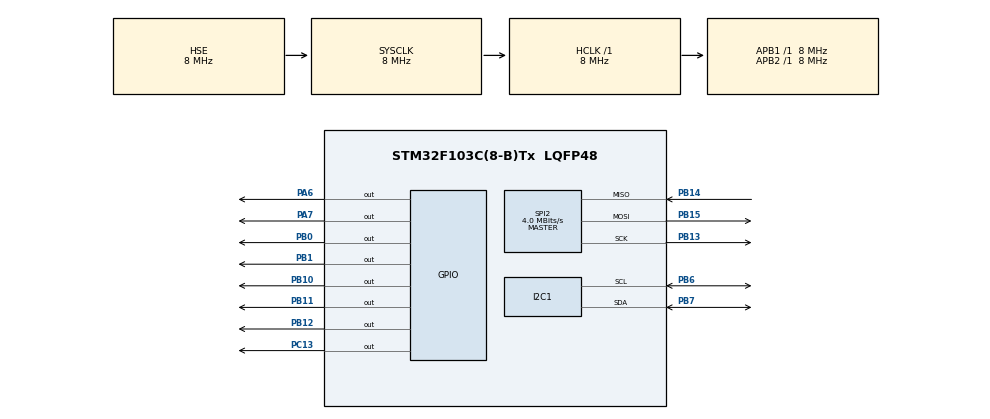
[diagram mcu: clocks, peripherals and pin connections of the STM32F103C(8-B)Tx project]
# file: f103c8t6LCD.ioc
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ADC1.Channel-0\#ChannelRegularConversion=ADC_CHANNEL_TEMPSENSOR
ADC1.NbrOfConversionFlag=1
ADC1.Rank-0\#ChannelRegularConversion=1
ADC1.SamplingTime-0\#ChannelRegularConversion=ADC_SAMPLETIME_1CYCLE_5
ADC1.master=1
Mcu.Family=STM32F1
Mcu.Name=STM32F103C(8-B)Tx
Mcu.Package=LQFP48
NVIC.PriorityGroup=NVIC_PRIORITYGROUP_4
PA6.Signal=GPIO_Output
PA7.Signal=GPIO_Output
PB0.Signal=GPIO_Output
PB1.Signal=GPIO_Output
PB10.Signal=GPIO_Output
PB11.Signal=GPIO_Output
PB12.Signal=GPIO_Output
PB13.Mode=Full_Duplex_Master
PB13.Signal=SPI2_SCK
PB14.Mode=Full_Duplex_Master
PB14.Signal=SPI2_MISO
PB15.Mode=Full_Duplex_Master
PB15.Signal=SPI2_MOSI
PB6.Mode=I2C
PB6.Signal=I2C1_SCL
PB7.Mode=I2C
PB7.Signal=I2C1_SDA
PC13-TAMPER-RTC.Signal=GPIO_Output
PC14-OSC32_IN.Mode=LSE-External-Oscillator
PC14-OSC32_IN.Signal=RCC_OSC32_IN
PC15-OSC32_OUT.Mode=LSE-External-Oscillator
PC15-OSC32_OUT.Signal=RCC_OSC32_OUT
PD0-OSC_IN.Mode=HSE-External-Oscillator
PD0-OSC_IN.Signal=RCC_OSC_IN
PD1-OSC_OUT.Mode=HSE-External-Oscillator
PD1-OSC_OUT.Signal=RCC_OSC_OUT
ProjectManager.HeapSize=0x200
ProjectManager.StackSize=0x400
ProjectManager.TargetToolchain=Makefile
RCC.AHBFreq_Value=8000000
RCC.APB1Freq_Value=8000000
RCC.APB1TimFreq_Value=8000000
RCC.APB2Freq_Value=8000000
RCC.APB2TimFreq_Value=8000000
RCC.HCLKFreq_Value=8000000
RCC.PLLSourceVirtual=RCC_PLLSOURCE_HSE
RCC.SYSCLKFreq_VALUE=8000000
RCC.SYSCLKSource=RCC_SYSCLKSOURCE_HSE
RCC.USBFreq_Value=16000000
SPI2.BaudRatePrescaler=SPI_BAUDRATEPRESCALER_2
SPI2.CalculateBaudRate=4.0 MBits/s
SPI2.Direction=SPI_DIRECTION_2LINES
SPI2.Mode=SPI_MODE_MASTER
SPI2.VirtualType=VM_MASTER
VP_ADC1_TempSens_Input.Mode=IN-TempSens
VP_SYS_VS_ND.Mode=No_Debug
board=custom

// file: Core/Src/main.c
/* USER CODE BEGIN Header */
/**
  ******************************************************************************
  * @file           : main.c
  * @brief          : Main program body
  ******************************************************************************
  * @attention
  *
  * Copyright (c) 2025 STMicroelectronics.
  * All rights reserved.
  *
  * This software is licensed under terms that can be found in the LICENSE file
  * in the root directory of this software component.
  * If no LICENSE file comes with this software, it is provided AS-IS.
  *
  ******************************************************************************
  */
/* USER CODE END Header */
#include "main.h"

ADC_HandleTypeDef hadc1;

I2C_HandleTypeDef hi2c1;

SPI_HandleTypeDef hspi2;

void SystemClock_Config(void);
static void MX_GPIO_Init(void);
static void MX_ADC1_Init(void);
static void MX_I2C1_Init(void);
static void MX_SPI2_Init(void);

int main(void)
{

  /* MCU Configuration--------------------------------------------------------*/

  /* Reset of all peripherals, Initializes the Flash interface and the Systick. */
  HAL_Init();

  /* Configure the system clock */
  SystemClock_Config();

  /* Initialize all configured peripherals */
  MX_GPIO_Init();
  MX_ADC1_Init();
  MX_I2C1_Init();
  MX_SPI2_Init();

  /* Infinite loop */
  /* USER CODE BEGIN WHILE */
  //while (1)
  //{
    /* USER CODE END WHILE */

    /* USER CODE BEGIN 3 */
  //}
	realmain();
  /* USER CODE END 3 */
}

void SystemClock_Config(void)
{
  RCC_OscInitTypeDef RCC_OscInitStruct = {0};
  RCC_ClkInitTypeDef RCC_ClkInitStruct = {0};
  RCC_PeriphCLKInitTypeDef PeriphClkInit = {0};

  /** Initializes the RCC Oscillators according to the specified parameters
  * in the RCC_OscInitTypeDef structure.
  */
  RCC_OscInitStruct.OscillatorType = RCC_OSCILLATORTYPE_HSE;
  RCC_OscInitStruct.HSEState = RCC_HSE_ON;
  RCC_OscInitStruct.PLL.PLLState = RCC_PLL_NONE;
  if (HAL_RCC_OscConfig(&RCC_OscInitStruct) != HAL_OK)
  {
    Error_Handler();
  }

  /** Initializes the CPU, AHB and APB buses clocks
  */
  RCC_ClkInitStruct.ClockType = RCC_CLOCKTYPE_HCLK|RCC_CLOCKTYPE_SYSCLK
                              |RCC_CLOCKTYPE_PCLK1|RCC_CLOCKTYPE_PCLK2;
  RCC_ClkInitStruct.SYSCLKSource = RCC_SYSCLKSOURCE_HSE;
  RCC_ClkInitStruct.AHBCLKDivider = RCC_SYSCLK_DIV1;
  RCC_ClkInitStruct.APB1CLKDivider = RCC_HCLK_DIV1;
  RCC_ClkInitStruct.APB2CLKDivider = RCC_HCLK_DIV1;

  if (HAL_RCC_ClockConfig(&RCC_ClkInitStruct, FLASH_LATENCY_0) != HAL_OK)
  {
    Error_Handler();
  }
  PeriphClkInit.PeriphClockSelection = RCC_PERIPHCLK_ADC;
  PeriphClkInit.AdcClockSelection = RCC_ADCPCLK2_DIV2;
  if (HAL_RCCEx_PeriphCLKConfig(&PeriphClkInit) != HAL_OK)
  {
    Error_Handler();
  }
}

static void MX_ADC1_Init(void)
{

  ADC_ChannelConfTypeDef sConfig = {0};

  /** Common config
  */
  hadc1.Instance = ADC1;
  hadc1.Init.ScanConvMode = ADC_SCAN_DISABLE;
  hadc1.Init.ContinuousConvMode = DISABLE;
  hadc1.Init.DiscontinuousConvMode = DISABLE;
  hadc1.Init.ExternalTrigConv = ADC_SOFTWARE_START;
  hadc1.Init.DataAlign = ADC_DATAALIGN_RIGHT;
  hadc1.Init.NbrOfConversion = 1;
  if (HAL_ADC_Init(&hadc1) != HAL_OK)
  {
    Error_Handler();
  }

  /** Configure Regular Channel
  */
  sConfig.Channel = ADC_CHANNEL_TEMPSENSOR;
  sConfig.Rank = ADC_REGULAR_RANK_1;
  sConfig.SamplingTime = ADC_SAMPLETIME_1CYCLE_5;
  if (HAL_ADC_ConfigChannel(&hadc1, &sConfig) != HAL_OK)
  {
    Error_Handler();
  }

}

static void MX_I2C1_Init(void)
{

  hi2c1.Instance = I2C1;
  hi2c1.Init.ClockSpeed = 100000;
  hi2c1.Init.DutyCycle = I2C_DUTYCYCLE_2;
  hi2c1.Init.OwnAddress1 = 0;
  hi2c1.Init.AddressingMode = I2C_ADDRESSINGMODE_7BIT;
  hi2c1.Init.DualAddressMode = I2C_DUALADDRESS_DISABLE;
  hi2c1.Init.OwnAddress2 = 0;
  hi2c1.Init.GeneralCallMode = I2C_GENERALCALL_DISABLE;
  hi2c1.Init.NoStretchMode = I2C_NOSTRETCH_DISABLE;
  if (HAL_I2C_Init(&hi2c1) != HAL_OK)
  {
    Error_Handler();
  }

}

static void MX_SPI2_Init(void)
{

  /* SPI2 parameter configuration*/
  hspi2.Instance = SPI2;
  hspi2.Init.Mode = SPI_MODE_MASTER;
  hspi2.Init.Direction = SPI_DIRECTION_2LINES;
  hspi2.Init.DataSize = SPI_DATASIZE_8BIT;
  hspi2.Init.CLKPolarity = SPI_POLARITY_LOW;
  hspi2.Init.CLKPhase = SPI_PHASE_1EDGE;
  hspi2.Init.NSS = SPI_NSS_SOFT;
  hspi2.Init.BaudRatePrescaler = SPI_BAUDRATEPRESCALER_2;
  hspi2.Init.FirstBit = SPI_FIRSTBIT_MSB;
  hspi2.Init.TIMode = SPI_TIMODE_DISABLE;
  hspi2.Init.CRCCalculation = SPI_CRCCALCULATION_DISABLE;
  hspi2.Init.CRCPolynomial = 10;
  if (HAL_SPI_Init(&hspi2) != HAL_OK)
  {
    Error_Handler();
  }

}

static void MX_GPIO_Init(void)
{
  GPIO_InitTypeDef GPIO_InitStruct = {0};

  /* GPIO Ports Clock Enable */
  __HAL_RCC_GPIOC_CLK_ENABLE();
  __HAL_RCC_GPIOD_CLK_ENABLE();
  __HAL_RCC_GPIOA_CLK_ENABLE();
  __HAL_RCC_GPIOB_CLK_ENABLE();

  /*Configure GPIO pin Output Level */
  HAL_GPIO_WritePin(GPIOC, GPIO_PIN_13, GPIO_PIN_RESET);

  /*Configure GPIO pin Output Level */
  HAL_GPIO_WritePin(GPIOA, GPIO_PIN_6|GPIO_PIN_7, GPIO_PIN_RESET);

  /*Configure GPIO pin Output Level */
  HAL_GPIO_WritePin(GPIOB, GPIO_PIN_0|GPIO_PIN_1|GPIO_PIN_10|GPIO_PIN_11
                          |GPIO_PIN_12, GPIO_PIN_RESET);

  /*Configure GPIO pin : PC13 */
  GPIO_InitStruct.Pin = GPIO_PIN_13;
  GPIO_InitStruct.Mode = GPIO_MODE_OUTPUT_PP;
  GPIO_InitStruct.Pull = GPIO_NOPULL;
  GPIO_InitStruct.Speed = GPIO_SPEED_FREQ_LOW;
  HAL_GPIO_Init(GPIOC, &GPIO_InitStruct);

  /*Configure GPIO pins : PA6 PA7 */
  GPIO_InitStruct.Pin = GPIO_PIN_6|GPIO_PIN_7;
  GPIO_InitStruct.Mode = GPIO_MODE_OUTPUT_PP;
  GPIO_InitStruct.Pull = GPIO_NOPULL;
  GPIO_InitStruct.Speed = GPIO_SPEED_FREQ_LOW;
  HAL_GPIO_Init(GPIOA, &GPIO_InitStruct);

  /*Configure GPIO pins : PB0 PB1 PB10 PB11
                           PB12 */
  GPIO_InitStruct.Pin = GPIO_PIN_0|GPIO_PIN_1|GPIO_PIN_10|GPIO_PIN_11
                          |GPIO_PIN_12;
  GPIO_InitStruct.Mode = GPIO_MODE_OUTPUT_PP;
  GPIO_InitStruct.Pull = GPIO_NOPULL;
  GPIO_InitStruct.Speed = GPIO_SPEED_FREQ_LOW;
  HAL_GPIO_Init(GPIOB, &GPIO_InitStruct);

}

void Error_Handler(void)
{
  __disable_irq();
}
